# psoc4100smax register map
Vendor: Infineon Technologies; Series: PSOC4100Smax; File version: 1.0
CPU: CM0PLUS r0p1, little endian, MPU, no FPU, VTOR, 2 interrupt priority bits, 32 interrupts
Registers are 32-bit, read-write, reset 0x0 unless marked. A register's access mark holds for its fields unless they carry their own. Offsets are from the block's base; [hi:lo] are bit positions; {n}, {i} and the like mark numbered series.

## CRYPTO — Cryptography component
Base 0x402C0000
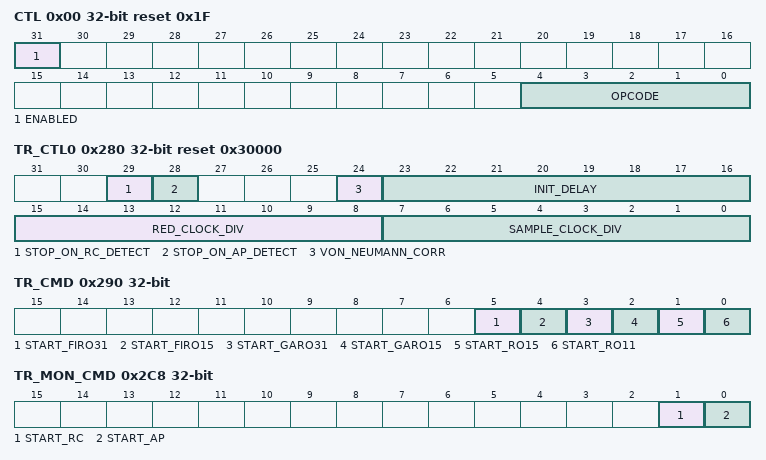
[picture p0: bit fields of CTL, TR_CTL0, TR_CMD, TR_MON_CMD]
0x00 CTL reset 0x1F — Control
  [31] ENABLED — IP enable: '0': Disabled. All non-retention registers (command and status registers) are reset to their default value when the IP is disabled. All retention registers retain their value when the IP is disabled. '1': Enabled.
  [4:0] OPCODE — Specifies the operation: '0': AES forward block cipher. '1': AES inverse block cipher. '16': SHA operation. '24': CRC operation. otherwise: undefined.
    0=AES_FORWARD (SRC_CTL0.OFFSET specifies the offset of the key (as used in the first cipher round) in the memory buffer. SRC_CTL1.OFFSET specifies the offset of the plaintext in the memory buffer. DST_CTL0.OFFSET specifies the offset of the key (as used by the last cipher round) in the memory buffer....); 1=AES_INVERSE (SRC_CTL0.OFFSET specifies the offset of the round key (as used in the first inverse cipher round) in the memory buffer. SRC_CTL1.OFFSET specifies the offset of the ciphertext in the memory buffer. DST_CTL0.OFFSET specifies the offset of the key (as used by the last inverse cipher round) in the memory buffer....); 16=SHA (SRC_CTL0.OFFSET specifies the offset of the message in the memory buffer. SRC_CTL1.OFFSET specifies the offset of the input hash in the memory buffer. DST_CTL0.OFFSET specifies the offset of a temporary buffer (to hold message schedule round constants) in the memory buffer....); 24=CRC (SRC_CTL0.OFFSET specifies the offset of the data in the memory buffer. When the operation has completed, the resulting CRC can be read from CRC_REM.)
0x04 STATUS ro
  [0] BUSY — Reflects the state of the component: '0': IP (AES, SHA, CRC component) is not busy. '1': IP (AES, SHA, CRC component) is busy performing a operation. An operation is started through the CMD register or through the 'tr_in' input trigger. When the IP is busy, it is NOT possible to start another operation. When the IP is busy, it is possible to access the memory buffer (to prepare for another operation).
0x08 CMD — Command
  [0] START write-1-sets — FW sets this field to '1' to start an operation as specified by CTL.OPCODE. HW sets this field to '0' to indicate that the operation has completed. HW can start an operation through the 'tr_in' input trigger. A rising edge ('0' to '1' transition) on this trigger starts an operation (as specified by CTL.OPCODE). When an operation completes, a two cycle '1' pulse (on 'clk_sys') is generated on the 'tr_out' output trigger. SW and HW control over the start of an operation should not be mixed. When an operation is busy (STATUS.BUSY is '1'), no new operation can be started. A SW write to START is ignored and a HW input trigger 'tr_in' rising edge is ignored.
0x10 SRC_CTL0 — Source control 0
  [10:2] OFFSET — Word (32-bit) offset of source 0 in the data buffer.
0x14 SRC_CTL1 — Source control 1
  [10:2] OFFSET — Word (32-bit) offset of source 1 in the data buffer.
0x20 DST_CTL0 — Destination control 0
  [10:2] OFFSET — Word (32-bit) offset of destination 0 in the data buffer.
0x24 DST_CTL1 — Destination control 1
  [10:2] OFFSET — Word (32-bit) offset of destination 1 in the data buffer.
0x100 AES_CTL — AES control
  [1:0] KEY_SIZE — AES key size: '0': 128-bit key, 10 rounds AES (inverse) cipher operation. SRC_CTL0 and DST_CTL0 specify the offset of a 16 Byte key in the memory buffer. '1': 192-bit key, 12 rounds AES (inverse) cipher operation. SRC_CTL0 and DST_CTL0 specify the offset of a 24 Byte key in the memory buffer. '2': 256-bit key, 14 rounds AES (inverse) cipher operation. SRC_CTL0 and DST_CTL0 specify the offset of a 32 Byte key in the memory buffer. '3': undefined
0x200 PR_CTL — Pseudo random control
  [31:0] MAX — Specifies the maximum random value of the pseudo random number generator: '0': produces a random number in the range {0} '1': produces a random number in the range [0, 1] '2': produces a random number in the range [0, 1, 2] '3': produces a random number in the range [0, 3] ... '(2^32)-1': produces a random number in the range [0, (2^32)-1].
0x208 PR_CMD — Pseudo random command
  [0] START — SW sets this field to '1' to start the pseudo ransom number generator. HW clears this field to '0' when the operation has completed and the resulting pseudo random number (in the range [0, PR_CTL.MAX]) can be read from PR_RESULT.
0x210 PR_LFSR_CTL0 — Pseudo random LFSR control 0
  [31:0] LFSR32 — State of a 32-bit Linear Feedback Shift Registers (LFSR) that is used to generate a pseudo random bit sequence. This register needs to be initialized by SW. The initialization value should be different from '0'. The three PR_LFSR_CTL registers represents the state of a 32-bit, 31-bit and 29-bit LFSR. Individually, these LFSRs generate a pseudo random bit sequence that repeats itself after (2^32)-1, (2^31)-1 and (2^29)-1 bits. The numbers (2^32)-1, (2^31)-1 and (2^29)-1 are relatively prime (their greatest common denominator is '1'). The three bit sequence are combined (XOR'd) into a single bitstream to create a pseudo random bit sequence that repeats itself after ((2^32)-1) * ((2^31)-1) * ((2*29)-1) bits. The following polynomials are used: - 32-bit irreducible polynomial: x^32+x^30+x^26+x^25+1. - 31-bit irreducible polynomial: x^31+x^28+1. - 29-bit irreducible polynomial: x^29+x^27+1.
0x214 PR_LFSR_CTL1 — Pseudo random LFSR control 1
  [30:0] LFSR31 — State of a 31-bit Linear Feedback Shift Registers (LFSR) that is used to generate a pseudo random bit sequence. See PR_LFSR_CTL0.
0x218 PR_LFSR_CTL2 — Pseudo random LFSR control 2
  [28:0] LFSR29 — State of a 29-bit Linear Feedback Shift Registers (LFSR) that is used to generate a pseudo random bit sequence. See PR_LFSR_CTL0.
0x220 PR_RESULT — Pseudo random status
  [31:0] DATA32 — Result of a pseudo random number generation operation. The resulting value DATA is in the range [0, PR_CTL.MAX]. HW generates the number in this field. Note that SW can write this field. This functionality can be used prevent information leakage from the privileged domain to the user domain.
0x280 TR_CTL0 reset 0x30000 — True random control 0
  [29] STOP_ON_RC_DETECT — Specifies if TRNG functionality is stopped on a repetition count test detection (when HW sets INTR.TR_RC_DETECT to '1'): '0': Functionality is NOT stopped. '1': Functionality is stopped (TR_CMD fields are set to '0' by HW).
  [28] STOP_ON_AP_DETECT — Specifies if TRNG functionality is stopped on an adaptive proportion test detection (when HW sets INTR.TR_AP_DETECT to '1'): '0': Functionality is NOT stopped. '1': Functionality is stopped (TR_CMD fields are set to '0' by HW).
  [24] VON_NEUMANN_CORR — Specifies if the 'von Neumann corrector' is disabled or enabled: '0': disabled. '1': enabled. The 'von Neumann corrector' post-processes the reduced bits to remove a '0' or '1' bias. The corrector operates on reduced bit pairs ('oldest bit, newest bit'): '00': no bit is produced. '01': '0' bit is produced (oldest bit). '10': '1' bit is produced (oldest bit). '11': no bit is produced. Note that the corrector produces bits at a random pace and at a frequency that is 1/4 of the reduced bit frequency (reduced bits are processed in pairs, and half of the pairs do NOT produce a bit).
  [23:16] INIT_DELAY — Specifies an initialization delay: number of removed/dropped samples before reduced bits are generated. This field should be programmed in the range [1, 255]. After starting the oscillators, at least the first 2 samples should be removed/dropped to clear the state of internal synchronizers. In addition, it is advised to drop the second 2 samples from the oscillators (to circumvent the semi-predictable oscillator startup behavior). This result in the default field value of '3'. Field encoding is as follows: '0': 1 sample is dropped. '1': 2 samples are dropped. ... '255': 256 samples are dropped. The TR_INITIALIZED interrupt cause is set to '1', when the initialization delay is passed.
  [15:8] RED_CLOCK_DIV — Specifies the clock divider that is used to produce reduced bits. '0': 1 reduced bit is produced for each sample. '1': 1 reduced bit is produced for each 2 samples. ... '255': 1 reduced bit is produced for each 256 samples. The reduced bits are considered random bits and shifted into TR_RESULT0.DATA32.
  [7:0] SAMPLE_CLOCK_DIV — Specifies the clock divider that is used to sample oscillator data. This clock divider is wrt. 'clk_sys'. '0': sample clock is 'clk_sys'. '1': sample clock is 'clk_sys'/2. ... '255': sample clock is 'clk_sys'/256.
0x284 TR_CTL1 reset 0x20 — True random control 1
  [5:0] DATA_BIT_SIZE — Specifies the number of desired of bits in the generated random number (legal range: [1, 32]). The TR_DATA_AVAILABLE interrupt cause is set to '1' when TR_RESULT1.DATA_BIT_SIZE >= DATA_BIT_SIZE.
0x288 TR_RESULT0 — True random result 0
  [31:0] DATA32 — Generated true random number. HW generates the number in this field. When a new random bit is generated, it is shifted into the lowest bit position (DATA32[0]) and the highest bit position (DATA32[31]) is shifted out. Note that SW can write this field. This functionality can be used prevent information leakage.
0x28C TR_RESULT1 — True random result 1
  [5:0] DATA_BIT_SIZE — Specifies the number of bits in the generated true random number (TR_RESULT0.DATA32). When a new random bit is generated, this field is incremented by '1'. The value is in the range [0, 32] (a saturating counter is used). Note that SW can write this field. This functionality can be used prevent information leakage. Typically, this field is updated/decremented in the interrupt handler. The interrupt handler decrements the field by the number of consumed bits. If the interrupt handler does NOT update this field (and TR_RESULT.DATA_BIT_SIZE is unchanged), the TR_DATA_AVAILABLE interrupt cause will remain activated. Therefore, proper interrupt based usage is as follows: - Consume bits from TR_RESULT0. - Write consumed bits in TR_RESULT0 to '0's (if information leakage needs to prevented). - Decrement TR_RESULT1 by the number of consumed bits. - Deactivate INTR.TR_DATA_AVAILABLE.
0x290 TR_CMD — True random command
  [5] START_FIRO31 — SW sets this field to '1' to start the programmable Fibonacci ring oscillator with up to 31 inverters. The TR_FIRO_CTL register specifies the programmable polynomial.
  [4] START_FIRO15 — SW sets this field to '1' to start the fixed Fibonacci ring oscillator with 15 inverters.
  [3] START_GARO31 — SW sets this field to '1' to start the programmable Galois ring oscillator with up to 31 inverters. The TR_GARO_CTL register specifies the programmable polynomial.
  [2] START_GARO15 — SW sets this field to '1' to start the fixed Galois ring oscillator with 15 inverters.
  [1] START_RO15 — SW sets this field to '1' to start the ring oscillator with 15 inverters.
  [0] START_RO11 — SW sets this field to '1' to start the ring oscillator with 11 inverters.
0x2A0 TR_GARO_CTL — True random GARO control
  [30:0] POLYNOMIAL31 — Polynomial for programmable Galois ring oscillator. The polynomial is represented WITHOUT the high order bit (this bit is always assumed '1'). The polynomial should be aligned such that the more significant bits (bit 30 and down) contain the polynomial and the less significant bits (bit 0 and up) contain padding '0's.
0x2A4 TR_FIRO_CTL — True random FIRO control
  [30:0] POLYNOMIAL31 — Polynomial for programmable Fibonacci ring oscillator. The polynomial is represented WITHOUT the high order bit (this bit is always assumed '1'). The polynomial should be aligned such that the more significant bits (bit 30 and down) contain the polynomial and the less significant bits (bit 0 and up) contain padding '0's.
0x2C0 TR_MON_CTL reset 0x2 — True random monitor control
  [1:0] BITSTREAM_SEL — Selection of the bitstream: '0': DAS bitstream. '1': RED bitstream. '2': TR bitstream. '3': Undefined.
0x2C8 TR_MON_CMD — True random monitor command
  [1] START_RC — Repetition count (RC) test enable: '0': Disabled. '1': Enabled. On a RC detection, HW sets this field to '0' and sets INTR.TR_RC_DETECT to '1.
  [0] START_AP — Adaptive proportion (AP) test enable: '0': Stopped. '1': Started. On a AP detection, HW sets this field to '0' and sets INTR.TR_AP_DETECT to '1.
0x2D0 TR_MON_RC_CTL reset 0xFF — True random monitor RC control
  [7:0] CUTOFF_COUNT8 — Cutoff count (legal range is [1, 255]): '0': Illegal. '1': 1 repetition. ... '255': 255 repetitions.
0x2D8 TR_MON_RC_STATUS0 ro — True random monitor RC status 0
  [0] BIT — Current active bit value: '0': '0'. '1': '1'. This field is only valid when TR_MON_RC_STATUS1.REP_COUNT is NOT equal to '0'.
0x2DC TR_MON_RC_STATUS1 ro — True random monitor RC status 1
  [7:0] REP_COUNT — Number of repetitions of the current active bit counter: '0': 0 repetitions. ... '255': 255 repetitions.
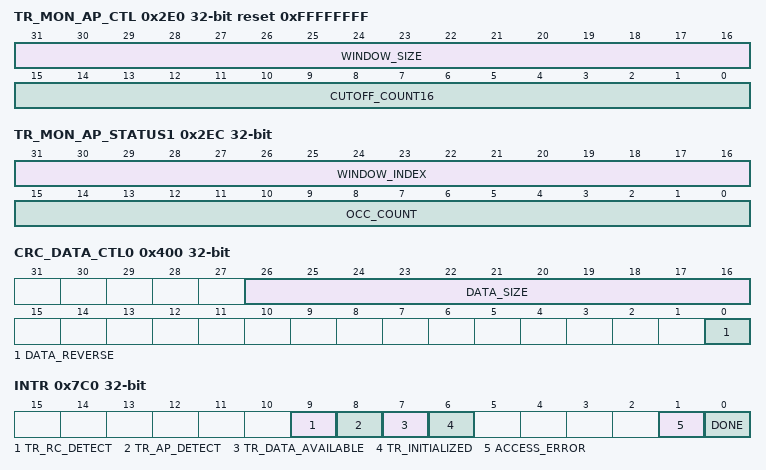
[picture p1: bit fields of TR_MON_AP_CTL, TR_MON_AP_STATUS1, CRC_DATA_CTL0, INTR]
0x2E0 TR_MON_AP_CTL reset 0xFFFFFFFF — True random monitor AP control
  [31:16] WINDOW_SIZE — Window size (minus 1) : '0': 1 bit. ... '65535': 65536 bits.
  [15:0] CUTOFF_COUNT16 — Cutoff count (legal range is [1, 65535]). '0': Illegal. '1': 1 occurance. ... '65535': 65535 occurances.
0x2E8 TR_MON_AP_STATUS0 ro — True random monitor AP status 0
  [0] BIT — Current active bit value: '0': '0'. '1': '1'. This field is only valid when TR_MON_AP_STATUS1.OCC_COUNT is NOT equal to '0'.
0x2EC TR_MON_AP_STATUS1 ro — True random monitor AP status 1
  [31:16] WINDOW_INDEX — Counter to keep track of the current index in the window (counts down from TR_MON_AP_CTL.WINDOW_SIZE to '0').
  [15:0] OCC_COUNT — Number of occurances of the current active bit counter: '0': 0 occurances ... '65535': 65535 occurances
0x300 SHA_CTL — SHA control
  [2:0] MODE — SHA mode: '0': SHA1. The message is 16 32 bits words: 64 Bytes. The hash is 5 32-bit words: 20 Bytes. There are 80 32-bit message schedule round constants: 320 Bytes. '1': SHA2_224, SHA2_256. The message is 16 32-bit words: 64 Bytes. The hash is 8 32-bit words: 32 Bytes. There are 64 32-bit message schedule round constants: 256 Bytes. The difference between SHA2-224 and SHA2-256 is entirely in software. '2': undefined '3': SHA2-384 (NOT supported) '4': SHA2-512 (NOT supported) '5': SHA2-512/224 (NOT supported) '6': SHA2-512/256 (NOT supported) '7': undefined
0x400 CRC_DATA_CTL0 — CRC data control 0
  [26:16] DATA_SIZE — Size of the data in bytes (the size is limited by the memory buffer size), the number bytes processed is DATA_SIZE+1: '0': 1 byte. '1': 2 bytes. ... '2047': 2048 bytes.
  [0] DATA_REVERSE — Specifies the bit order in which a data byte is processed (reversal is performed after XORing): '0': Most significant bit (bit 1) first. '1': Least significant bit (bit 0) first.
0x404 CRC_DATA_CTL1 — CRC data control 1
  [7:0] DATA_XOR — Specifies a byte mask with which each data byte is XOR'd. The XOR is performed before data reversal.
0x410 CRC_POL_CTL — CRC polynomial control
  [31:0] POLYNOMIAL — CRC polynomial. The polynomial is represented without the high order bit (this bit is always assumed '1'). The polynomial should be aligned such that the more significant bits (bit 31 and down) contain the polynomial and the less significant bits (bit 0 and up) contain padding '0's. Some frequently used polynomials: - CRC32: POLYNOMIAL is 0x04c11db7. - CRC16: POLYNOMIAL is 0x80050000. - CRC16 CCITT: POLYNOMIAL is 0x10210000.
0x414 CRC_LFSR_CTL — CRC LFSR control
  [31:0] LFSR32 — State of a 32-bit Linear Feedback Shift Registers (LFSR) that is used to implement CRC. This register needs to be initialized by SW to provide the CRC seed value. The seed value should be aligned such that the more significant bits (bit 31 and down) contain the seed value and the less significant bits (bit 0 and up) contain padding '0's.
0x420 CRC_REM_CTL0 — CRC remainder control 0
  [0] REM_REVERSE — Specifies whether the remainder is bit reversed (reversal is performed after XORing): '0': No. '1': Yes.
0x424 CRC_REM_CTL1 — CRC remainder control 1
  [31:0] REM_XOR — Specifies a mask with which the LFSR register is XOR'd to produce a remainder. The XOR is performed before remainder reversal.
0x428 CRC_REM ro reset not defined — CRC remainder status
  [31:0] REM — Remainder value. The alignment of the remainder depends on CRC_REM_CTL0.REM_REVERSE: '0': the more significant bits (bit 31 and down) contain the remainder. '1': the less significant bits (bit 0 and up) contain the remainder.
0x7C0 INTR — Interrupt request
  [9] TR_RC_DETECT write-1-clears — This interrupt cause is activated (HW sets the field to '1') when the true random number generator monitor adaptive proportion test detects a disproportionate occurrence of a specific bit value.
  [8] TR_AP_DETECT write-1-clears — This interrupt cause is activated (HW sets the field to '1') when the true random number generator monitor repetition count test detects a repetition of a specific bit value.
  [7] TR_DATA_AVAILABLE write-1-clears — This interrupt cause is activated (HW sets the field to '1') when the true random number generator has generated a data value of the specified bit size: (TR_RESULT.DATA_BIT_SIZE >= TR_CTL.DATA_BIT_SIZE). See TR_RESULT1.DATA_BIT_SIZE for proper deactivation of this interrupt cause.
  [6] TR_INITIALIZED write-1-clears — This interrupt cause is activated (HW sets the field to '1') when the true random number generator is initialized.
  [1] ACCESS_ERROR write-1-clears — This interrupt cause is activated (HW sets the field to '1') when a command/operation is aborted due to a user/privileged mode violation of the buffer accesses.
  [0] DONE write-1-clears — This interrupt cause is activated (HW sets the field to '1') when a command/operation completes. SW writes a '1' to this field to clear the interrupt cause. As an alternative to interrupt driven operation, SW can poll the STATUS.BUSY field to determine completion of an operation.
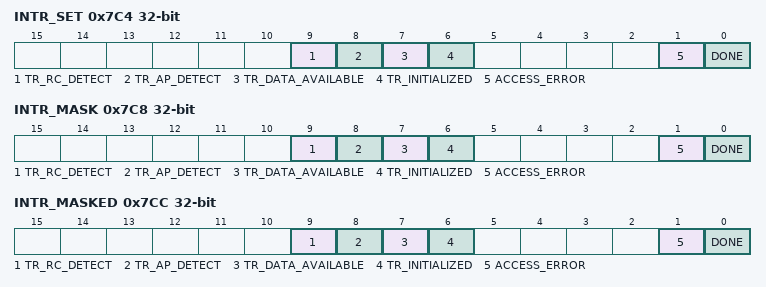
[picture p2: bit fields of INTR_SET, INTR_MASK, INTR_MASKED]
0x7C4 INTR_SET — Interrupt set request
  [9] TR_RC_DETECT write-1-sets — SW writes a '1' to this field to set the corresponding field in interrupt request register.
  [8] TR_AP_DETECT write-1-sets — SW writes a '1' to this field to set the corresponding field in interrupt request register.
  [7] TR_DATA_AVAILABLE write-1-sets — SW writes a '1' to this field to set the corresponding field in interrupt request register.
  [6] TR_INITIALIZED write-1-sets — SW writes a '1' to this field to set the corresponding field in interrupt request register.
  [1] ACCESS_ERROR write-1-sets — SW writes a '1' to this field to set the corresponding field in interrupt request register.
  [0] DONE write-1-sets — SW writes a '1' to this field to set the corresponding field in interrupt request register.
0x7C8 INTR_MASK — Interrupt mask
  [9] TR_RC_DETECT — Mask bit for corresponding field in interrupt request register.
  [8] TR_AP_DETECT — Mask bit for corresponding field in interrupt request register.
  [7] TR_DATA_AVAILABLE — Mask bit for corresponding field in interrupt request register.
  [6] TR_INITIALIZED — Mask bit for corresponding field in interrupt request register.
  [1] ACCESS_ERROR — Mask bit for corresponding field in interrupt request register.
  [0] DONE — Mask bit for corresponding field in interrupt request register.
0x7CC INTR_MASKED ro — Interrupt masked
  [9] TR_RC_DETECT — Logical and of corresponding request and mask bits.
  [8] TR_AP_DETECT — Logical and of corresponding request and mask bits.
  [7] TR_DATA_AVAILABLE — Logical and of corresponding request and mask bits.
  [6] TR_INITIALIZED — Logical and of corresponding request and mask bits.
  [1] ACCESS_ERROR — Logical and of corresponding request and mask bits.
  [0] DONE — Logical and of corresponding request and mask bits.
0xFF00 PRIV_BUF — Buffer Privilege register
  [2:0] BUF_PRIV_LIMIT — Indicates how big the privileged area of the Buffer is in power of 2 bytes, i.e. first 2^(BUF_PRIV_LIMIT+4) Bytes are Privileged, with the exception of the 0 value. '0': Entire Buffer is user mode accessible '1': First 32 Bytes are Privileged. '2': First 64 Bytes are Privileged. ... '6': First 1024 Bytes are Privileged. '7': First 2048 Bytes are Privileged. 2^(BUF_PRIV_LIMIT+5) >= 'Buffer capacity': Entire buffer is Privileged (note this disables the CRC operation which requires user memory to operate).

## Notices in the file
(c) 2016-2026, Infineon Technologies AG or an affiliate of
Infineon Technologies AG.
SPDX-License-Identifier: Apache-2.0
Licensed under the Apache License, Version 2.0 (the "License");
you may not use this file except in compliance with the License.
You may obtain a copy of the License at
http://www.apache.org/licenses/LICENSE-2.0
Unless required by applicable law or agreed to in writing, software
distributed under the License is distributed on an "AS IS" BASIS,
WITHOUT WARRANTIES OR CONDITIONS OF ANY KIND, either express or implied.
See the License for the specific language governing permissions and
limitations under the License.
